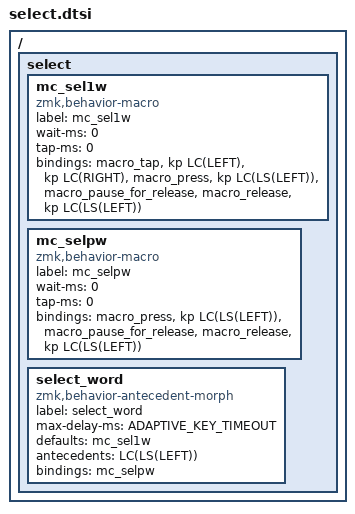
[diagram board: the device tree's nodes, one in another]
/*
*
* Copyright (c) 2022 Rafael Romão
* SPDX-License-Identifier: MIT
*
*/

/ {
    select {
        
        // Select Word

        mc_sel1w: mc_sel1w {
			compatible = "zmk,behavior-macro";
            label = "mc_sel1w";
            #binding-cells = <0>;
            wait-ms = <0>;
            tap-ms = <0>;
            bindings = <&macro_tap &kp LC(LEFT) &kp LC(RIGHT) &macro_press &kp LC(LS(LEFT)) &macro_pause_for_release &macro_release &kp LC(LS(LEFT))>;
        };
        mc_selpw: mc_selpw {
			compatible = "zmk,behavior-macro";
            label = "mc_selpw";
            #binding-cells = <0>;
            wait-ms = <0>;
            tap-ms = <0>;
            bindings = <&macro_press &kp LC(LS(LEFT)) &macro_pause_for_release &macro_release &kp LC(LS(LEFT))>;
        };
        select_word: select_word {
            compatible = "zmk,behavior-antecedent-morph";
            label = "select_word";
            #binding-cells = <0>;
            max-delay-ms = <ADAPTIVE_KEY_TIMEOUT>;
            defaults = <&mc_sel1w>;
            antecedents = <LC(LS(LEFT))>;
            bindings = <&mc_selpw>;
        };
   };
};
